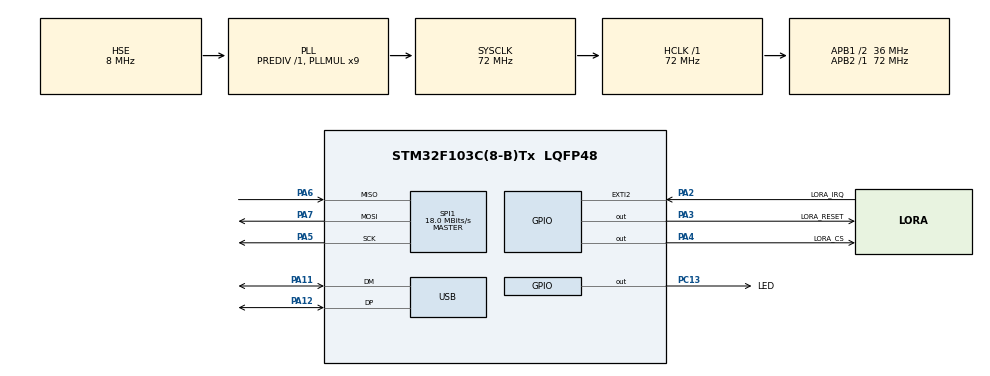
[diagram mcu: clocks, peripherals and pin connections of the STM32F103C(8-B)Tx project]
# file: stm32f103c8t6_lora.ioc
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Mcu.Family=STM32F1
PA6.Mode=Full_Duplex_Master
USB_DEVICE.CLASS_NAME_FS=CDC
PA7.Mode=Full_Duplex_Master
PD1-OSC_OUT.Mode=HSE-External-Oscillator
SPI1.VirtualType=VM_MASTER
USB_DEVICE.VirtualModeFS=Cdc_FS
PC13-TAMPER-RTC.Signal=GPIO_Output
RCC.USBPrescaler=RCC_USBCLKSOURCE_PLL_DIV1_5
PA11.Mode=Device
PD0-OSC_IN.Signal=RCC_OSC_IN
RCC.APB1CLKDivider=RCC_HCLK_DIV2
RCC.SYSCLKSource=RCC_SYSCLKSOURCE_PLLCLK
ProjectManager.StackSize=0x400
PD1-OSC_OUT.Signal=RCC_OSC_OUT
PA13.Signal=SYS_JTMS-SWDIO
PA12.Signal=USB_DP
ProjectManager.TargetToolchain=Makefile
SPI1.Direction=SPI_DIRECTION_2LINES
RCC.HCLKFreq_Value=72000000
VP_USB_DEVICE_VS_USB_DEVICE_CDC_FS.Mode=CDC_FS
RCC.APB2TimFreq_Value=72000000
SPI1.CalculateBaudRate=18.0 MBits/s
RCC.USBFreq_Value=48000000
RCC.AHBFreq_Value=72000000
PD0-OSC_IN.Mode=HSE-External-Oscillator
PA5.Signal=SPI1_SCK
board=custom
PC13-TAMPER-RTC.GPIO_Label=LED
RCC.PLLMUL=RCC_PLL_MUL9
RCC.APB2Freq_Value=72000000
SPI1.Mode=SPI_MODE_MASTER
PA14.Mode=Serial_Wire
NVIC.USB_LP_CAN1_RX0_IRQn=true\:0\:0\:false\:false\:true\:false\:true
PA13.Mode=Serial_Wire
Mcu.Name=STM32F103C(8-B)Tx
PA2.Signal=GPXTI2
PA4.Signal=GPIO_Output
RCC.SYSCLKFreq_VALUE=72000000
Mcu.Package=LQFP48
PA6.Signal=SPI1_MISO
PA12.Mode=Device
PA2.GPIO_Label=LORA_IRQ
PA11.Signal=USB_DM
PA14.Signal=SYS_JTCK-SWCLK
ProjectManager.HeapSize=0x200
NVIC.PriorityGroup=NVIC_PRIORITYGROUP_4
NVIC.EXTI2_IRQn=true\:0\:0\:false\:false\:true\:true\:true
RCC.APB1TimFreq_Value=72000000
RCC.APB1Freq_Value=36000000
SPI1.BaudRatePrescaler=SPI_BAUDRATEPRESCALER_4
USB_DEVICE.VirtualMode=Cdc
PA4.GPIO_Label=LORA_CS
PA3.GPIO_Label=LORA_RESET
PA3.Signal=GPIO_Output
PA5.Mode=Full_Duplex_Master
PA7.Signal=SPI1_MOSI

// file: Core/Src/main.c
/* USER CODE BEGIN Header */
/**
  ******************************************************************************
  * @file           : main.c
  * @brief          : Main program body
  ******************************************************************************
  * @attention
  *
  * <h2><center>&copy; Copyright (c) 2020 STMicroelectronics.
  * All rights reserved.</center></h2>
  *
  * This software component is licensed by ST under Ultimate Liberty license
  * SLA0044, the "License"; You may not use this file except in compliance with
  * the License. You may obtain a copy of the License at:
  *                             www.st.com/SLA0044
  *
  ******************************************************************************
  */
/* USER CODE END Header */

#include "main.h"
#include "spi.h"
#include "usb_device.h"
#include "gpio.h"

/* USER CODE BEGIN Includes */
#include "app.h"
/* USER CODE END Includes */

void SystemClock_Config(void);

int main(void)
{

  /* MCU Configuration--------------------------------------------------------*/

  /* Reset of all peripherals, Initializes the Flash interface and the Systick. */
  HAL_Init();

  /* Configure the system clock */
  SystemClock_Config();

  /* USER CODE BEGIN SysInit */
  app_init_f();
  /* USER CODE END SysInit */

  /* Initialize all configured peripherals */
  MX_GPIO_Init();
  MX_SPI1_Init();
  MX_USB_DEVICE_Init();
  /* USER CODE BEGIN 2 */
  app_init();
  /* USER CODE END 2 */

  /* Infinite loop */
  /* USER CODE BEGIN WHILE */
  app_loop();
  while (1)
  {
    /* USER CODE END WHILE */

  }
}

void SystemClock_Config(void)
{
  RCC_OscInitTypeDef RCC_OscInitStruct = {0};
  RCC_ClkInitTypeDef RCC_ClkInitStruct = {0};
  RCC_PeriphCLKInitTypeDef PeriphClkInit = {0};

  /** Initializes the CPU, AHB and APB busses clocks
  */
  RCC_OscInitStruct.OscillatorType = RCC_OSCILLATORTYPE_HSE;
  RCC_OscInitStruct.HSEState = RCC_HSE_ON;
  RCC_OscInitStruct.HSEPredivValue = RCC_HSE_PREDIV_DIV1;
  RCC_OscInitStruct.HSIState = RCC_HSI_ON;
  RCC_OscInitStruct.PLL.PLLState = RCC_PLL_ON;
  RCC_OscInitStruct.PLL.PLLSource = RCC_PLLSOURCE_HSE;
  RCC_OscInitStruct.PLL.PLLMUL = RCC_PLL_MUL9;
  if (HAL_RCC_OscConfig(&RCC_OscInitStruct) != HAL_OK)
  {
    Error_Handler();
  }
  /** Initializes the CPU, AHB and APB busses clocks
  */
  RCC_ClkInitStruct.ClockType = RCC_CLOCKTYPE_HCLK|RCC_CLOCKTYPE_SYSCLK
                              |RCC_CLOCKTYPE_PCLK1|RCC_CLOCKTYPE_PCLK2;
  RCC_ClkInitStruct.SYSCLKSource = RCC_SYSCLKSOURCE_PLLCLK;
  RCC_ClkInitStruct.AHBCLKDivider = RCC_SYSCLK_DIV1;
  RCC_ClkInitStruct.APB1CLKDivider = RCC_HCLK_DIV2;
  RCC_ClkInitStruct.APB2CLKDivider = RCC_HCLK_DIV1;

  if (HAL_RCC_ClockConfig(&RCC_ClkInitStruct, FLASH_LATENCY_2) != HAL_OK)
  {
    Error_Handler();
  }
  PeriphClkInit.PeriphClockSelection = RCC_PERIPHCLK_USB;
  PeriphClkInit.UsbClockSelection = RCC_USBCLKSOURCE_PLL_DIV1_5;
  if (HAL_RCCEx_PeriphCLKConfig(&PeriphClkInit) != HAL_OK)
  {
    Error_Handler();
  }
}

void Error_Handler(void)
{
}

/************************ (C) COPYRIGHT STMicroelectronics *****END OF FILE****/
